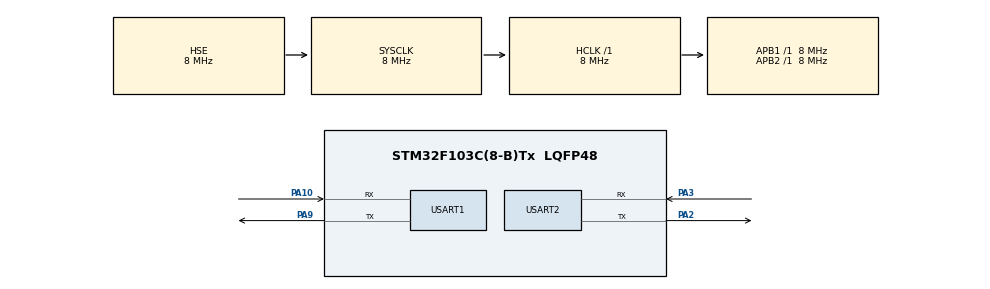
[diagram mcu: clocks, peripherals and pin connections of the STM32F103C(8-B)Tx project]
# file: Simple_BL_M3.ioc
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Mcu.Family=STM32F1
Mcu.Name=STM32F103C(8-B)Tx
Mcu.Package=LQFP48
NVIC.PriorityGroup=NVIC_PRIORITYGROUP_4
PA10.Mode=Asynchronous
PA10.Signal=USART1_RX
PA2.Mode=Asynchronous
PA2.Signal=USART2_TX
PA3.Mode=Asynchronous
PA3.Signal=USART2_RX
PA9.Mode=Asynchronous
PA9.Signal=USART1_TX
PD0-OSC_IN.Mode=HSE-External-Oscillator
PD0-OSC_IN.Signal=RCC_OSC_IN
PD1-OSC_OUT.Mode=HSE-External-Oscillator
PD1-OSC_OUT.Signal=RCC_OSC_OUT
ProjectManager.HeapSize=0x200
ProjectManager.StackSize=0x400
ProjectManager.TargetToolchain=MDK-ARM V5.32
RCC.AHBFreq_Value=8000000
RCC.APB1Freq_Value=8000000
RCC.APB1TimCLKDivider=2
RCC.APB1TimFreq_Value=16000000
RCC.APB2Freq_Value=8000000
RCC.APB2TimFreq_Value=8000000
RCC.HCLKFreq_Value=8000000
RCC.PLLSourceVirtual=RCC_PLLSOURCE_HSE
RCC.SYSCLKFreq_VALUE=8000000
RCC.SYSCLKSource=RCC_SYSCLKSOURCE_HSE
RCC.USBFreq_Value=16000000
USART1.VirtualMode=VM_ASYNC
USART2.VirtualMode=VM_ASYNC
VP_CRC_VS_CRC.Mode=CRC_Activate
VP_SYS_VS_ND.Mode=No_Debug
board=custom

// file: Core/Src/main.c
/* USER CODE BEGIN Header */
/**
  ******************************************************************************
  * @file           : main.c
  * @brief          : Main program body
  ******************************************************************************
  * @attention
  *
  * <h2><center>&copy; Copyright (c) 2023 STMicroelectronics.
  * All rights reserved.</center></h2>
  *
  * This software component is licensed by ST under BSD 3-Clause license,
  * the "License"; You may not use this file except in compliance with the
  * License. You may obtain a copy of the License at:
  *                        opensource.org/licenses/BSD-3-Clause
  *
  ******************************************************************************
  */
/* USER CODE END Header */
#include "main.h"
#include "crc.h"
#include "usart.h"
#include "gpio.h"

/* USER CODE BEGIN Includes */
#include "bootloader.h"
/* USER CODE END Includes */

void SystemClock_Config(void);

/* USER CODE BEGIN 0 */
char message_1[]= "I am Romany Sobhy%d\r\n";
char message_2[]= "I am Fine%d\r\n";
/* USER CODE END 0 */

int main(void)
{
  /* USER CODE BEGIN 1 */
uint32_t number=0;
  /* USER CODE END 1 */

  /* MCU Configuration--------------------------------------------------------*/

  /* Reset of all peripherals, Initializes the Flash interface and the Systick. */
  HAL_Init();

  /* Configure the system clock */
  SystemClock_Config();

  /* Initialize all configured peripherals */
  MX_GPIO_Init();
  MX_USART1_UART_Init();
  MX_USART2_UART_Init();
  MX_CRC_Init();
  /* USER CODE BEGIN 2 */
BL_status status=BL_NACK;
  /* USER CODE END 2 */

	 #if (BL_DEBUG_ENABLE == DEBUG_INFO_ENABLE)
	BL_Print_Message("Bootloader started...\r\n");
	 #endif

  /* Infinite loop */
  while (1)
  {

    /* USER CODE BEGIN 3 */
  BL_Print_Message(message_1,number);
	HAL_Delay(500);
	BL_Print_Message(message_2,number);
	HAL_Delay(500);
		number++;
	status=BL_UART_FETCH_HOST_COMMAND();
	}

  /* USER CODE END 3 */
}

void SystemClock_Config(void)
{
  RCC_OscInitTypeDef RCC_OscInitStruct = {0};
  RCC_ClkInitTypeDef RCC_ClkInitStruct = {0};

  /** Initializes the RCC Oscillators according to the specified parameters
  * in the RCC_OscInitTypeDef structure.
  */
  RCC_OscInitStruct.OscillatorType = RCC_OSCILLATORTYPE_HSE;
  RCC_OscInitStruct.HSEState = RCC_HSE_ON;
  RCC_OscInitStruct.PLL.PLLState = RCC_PLL_NONE;
  if (HAL_RCC_OscConfig(&RCC_OscInitStruct) != HAL_OK)
  {
    Error_Handler();
  }
  /** Initializes the CPU, AHB and APB buses clocks
  */
  RCC_ClkInitStruct.ClockType = RCC_CLOCKTYPE_HCLK|RCC_CLOCKTYPE_SYSCLK
                              |RCC_CLOCKTYPE_PCLK1|RCC_CLOCKTYPE_PCLK2;
  RCC_ClkInitStruct.SYSCLKSource = RCC_SYSCLKSOURCE_HSE;
  RCC_ClkInitStruct.AHBCLKDivider = RCC_SYSCLK_DIV1;
  RCC_ClkInitStruct.APB1CLKDivider = RCC_HCLK_DIV1;
  RCC_ClkInitStruct.APB2CLKDivider = RCC_HCLK_DIV1;

  if (HAL_RCC_ClockConfig(&RCC_ClkInitStruct, FLASH_LATENCY_0) != HAL_OK)
  {
    Error_Handler();
  }
}

void Error_Handler(void)
{
  __disable_irq();
  while (1)
  {
  }
}

/************************ (C) COPYRIGHT STMicroelectronics *****END OF FILE****/
